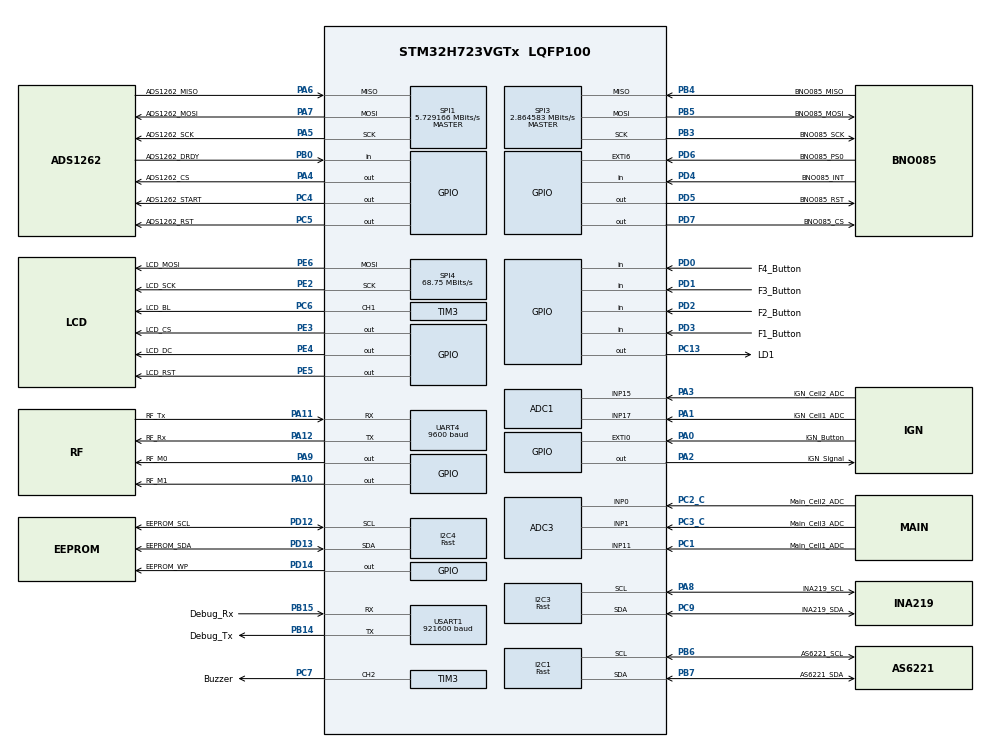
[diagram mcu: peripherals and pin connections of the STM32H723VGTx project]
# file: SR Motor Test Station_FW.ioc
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ADC1.Channel-0\#ChannelRegularConversion=ADC_CHANNEL_17
ADC1.Channel-1\#ChannelRegularConversion=ADC_CHANNEL_15
ADC1.ClockPrescaler=ADC_CLOCK_ASYNC_DIV4
ADC1.ClockPrescalerADC3=ADC_CLOCK_ASYNC_DIV4
ADC1.ContinuousConvMode=ENABLE
ADC1.ConversionDataManagement=ADC_CONVERSIONDATA_DMA_CIRCULAR
ADC1.NbrOfConversion=2
ADC1.NbrOfConversionFlag=1
ADC1.OffsetNumber-0\#ChannelRegularConversion=ADC_OFFSET_NONE
ADC1.OffsetNumber-1\#ChannelRegularConversion=ADC_OFFSET_NONE
ADC1.OffsetSignedSaturation-0\#ChannelRegularConversion=DISABLE
ADC1.OffsetSignedSaturation-1\#ChannelRegularConversion=DISABLE
ADC1.Rank-0\#ChannelRegularConversion=1
ADC1.Rank-1\#ChannelRegularConversion=2
ADC1.SamplingTime-0\#ChannelRegularConversion=ADC_SAMPLETIME_387CYCLES_5
ADC1.SamplingTime-1\#ChannelRegularConversion=ADC_SAMPLETIME_387CYCLES_5
ADC1.master=1
ADC3.Channel-0\#ChannelRegularConversion=ADC_CHANNEL_11
ADC3.Channel-1\#ChannelRegularConversion=ADC_CHANNEL_0
ADC3.Channel-2\#ChannelRegularConversion=ADC_CHANNEL_1
ADC3.ClockPrescaler=ADC_CLOCK_ASYNC_DIV4
ADC3.ClockPrescalerADC3=ADC_CLOCK_ASYNC_DIV4
ADC3.ContinuousConvMode=ENABLE
ADC3.ConversionDataManagement=ADC_CONVERSIONDATA_DMA_CIRCULAR
ADC3.DMAContinuousRequests=ENABLE
ADC3.DiscontinuousConvMode=DISABLE
ADC3.NbrOfConversion=3
ADC3.NbrOfConversionFlag=1
ADC3.OffsetNumber-0\#ChannelRegularConversion=ADC_OFFSET_NONE
ADC3.OffsetNumber-1\#ChannelRegularConversion=ADC_OFFSET_NONE
ADC3.OffsetNumber-2\#ChannelRegularConversion=ADC_OFFSET_NONE
ADC3.OffsetSign-0\#ChannelRegularConversion=ADC3_OFFSET_SIGN_NEGATIVE
ADC3.OffsetSign-1\#ChannelRegularConversion=ADC3_OFFSET_SIGN_NEGATIVE
ADC3.OffsetSign-2\#ChannelRegularConversion=ADC3_OFFSET_SIGN_NEGATIVE
ADC3.Rank-0\#ChannelRegularConversion=1
ADC3.Rank-1\#ChannelRegularConversion=2
ADC3.Rank-2\#ChannelRegularConversion=3
ADC3.SamplingTime-0\#ChannelRegularConversion=ADC3_SAMPLETIME_247CYCLES_5
ADC3.SamplingTime-1\#ChannelRegularConversion=ADC3_SAMPLETIME_247CYCLES_5
ADC3.SamplingTime-2\#ChannelRegularConversion=ADC3_SAMPLETIME_247CYCLES_5
CORTEX_M7.CPU_DCache=Enabled
CORTEX_M7.CPU_ICache=Enabled
CORTEX_M7.default_mode_Activation=1
Dma.ADC1.0.Direction=DMA_PERIPH_TO_MEMORY
Dma.ADC1.0.EventEnable=DISABLE
Dma.ADC1.0.FIFOMode=DMA_FIFOMODE_DISABLE
Dma.ADC1.0.Instance=DMA1_Stream0
Dma.ADC1.0.MemDataAlignment=DMA_MDATAALIGN_HALFWORD
Dma.ADC1.0.MemInc=DMA_MINC_ENABLE
Dma.ADC1.0.Mode=DMA_CIRCULAR
Dma.ADC1.0.PeriphDataAlignment=DMA_PDATAALIGN_HALFWORD
Dma.ADC1.0.PeriphInc=DMA_PINC_DISABLE
Dma.ADC1.0.Polarity=HAL_DMAMUX_REQ_GEN_RISING
Dma.ADC1.0.Priority=DMA_PRIORITY_LOW
Dma.ADC1.0.RequestNumber=1
Dma.ADC1.0.SignalID=NONE
Dma.ADC1.0.SyncEnable=DISABLE
Dma.ADC1.0.SyncPolarity=HAL_DMAMUX_SYNC_NO_EVENT
Dma.ADC1.0.SyncRequestNumber=1
Dma.ADC1.0.SyncSignalID=NONE
Dma.ADC3.1.Direction=DMA_PERIPH_TO_MEMORY
Dma.ADC3.1.EventEnable=DISABLE
Dma.ADC3.1.FIFOMode=DMA_FIFOMODE_DISABLE
Dma.ADC3.1.Instance=DMA1_Stream1
Dma.ADC3.1.MemDataAlignment=DMA_MDATAALIGN_HALFWORD
Dma.ADC3.1.MemInc=DMA_MINC_ENABLE
Dma.ADC3.1.Mode=DMA_CIRCULAR
Dma.ADC3.1.PeriphDataAlignment=DMA_PDATAALIGN_HALFWORD
Dma.ADC3.1.PeriphInc=DMA_PINC_DISABLE
Dma.ADC3.1.Polarity=HAL_DMAMUX_REQ_GEN_RISING
Dma.ADC3.1.Priority=DMA_PRIORITY_LOW
Dma.ADC3.1.RequestNumber=1
Dma.ADC3.1.SignalID=NONE
Dma.ADC3.1.SyncEnable=DISABLE
Dma.ADC3.1.SyncPolarity=HAL_DMAMUX_SYNC_NO_EVENT
Dma.ADC3.1.SyncRequestNumber=1
Dma.ADC3.1.SyncSignalID=NONE
Dma.Request0=ADC1
Dma.Request1=ADC3
Dma.Request2=USART1_TX
Dma.Request3=SPI4_TX
Dma.SPI4_TX.3.Direction=DMA_MEMORY_TO_PERIPH
Dma.SPI4_TX.3.EventEnable=DISABLE
Dma.SPI4_TX.3.FIFOMode=DMA_FIFOMODE_DISABLE
Dma.SPI4_TX.3.Instance=DMA1_Stream3
Dma.SPI4_TX.3.MemDataAlignment=DMA_MDATAALIGN_BYTE
Dma.SPI4_TX.3.MemInc=DMA_MINC_ENABLE
Dma.SPI4_TX.3.Mode=DMA_NORMAL
Dma.SPI4_TX.3.PeriphDataAlignment=DMA_PDATAALIGN_BYTE
Dma.SPI4_TX.3.PeriphInc=DMA_PINC_DISABLE
Dma.SPI4_TX.3.Polarity=HAL_DMAMUX_REQ_GEN_RISING
Dma.SPI4_TX.3.Priority=DMA_PRIORITY_HIGH
Dma.SPI4_TX.3.RequestNumber=1
Dma.SPI4_TX.3.SignalID=NONE
Dma.SPI4_TX.3.SyncEnable=DISABLE
Dma.SPI4_TX.3.SyncPolarity=HAL_DMAMUX_SYNC_NO_EVENT
Dma.SPI4_TX.3.SyncRequestNumber=1
Dma.SPI4_TX.3.SyncSignalID=NONE
Dma.USART1_TX.2.Direction=DMA_MEMORY_TO_PERIPH
Dma.USART1_TX.2.EventEnable=DISABLE
Dma.USART1_TX.2.FIFOMode=DMA_FIFOMODE_DISABLE
Dma.USART1_TX.2.Instance=DMA1_Stream2
Dma.USART1_TX.2.MemDataAlignment=DMA_MDATAALIGN_BYTE
Dma.USART1_TX.2.MemInc=DMA_MINC_ENABLE
Dma.USART1_TX.2.Mode=DMA_NORMAL
Dma.USART1_TX.2.PeriphDataAlignment=DMA_PDATAALIGN_BYTE
Dma.USART1_TX.2.PeriphInc=DMA_PINC_DISABLE
Dma.USART1_TX.2.Polarity=HAL_DMAMUX_REQ_GEN_RISING
Dma.USART1_TX.2.Priority=DMA_PRIORITY_LOW
Dma.USART1_TX.2.RequestNumber=1
Dma.USART1_TX.2.SignalID=NONE
Dma.USART1_TX.2.SyncEnable=DISABLE
Dma.USART1_TX.2.SyncPolarity=HAL_DMAMUX_SYNC_NO_EVENT
Dma.USART1_TX.2.SyncRequestNumber=1
Dma.USART1_TX.2.SyncSignalID=NONE
I2C1.I2C_Speed_Mode=I2C_Fast
I2C1.Timing=0x00D049FB
I2C3.I2C_Speed_Mode=I2C_Fast
I2C3.Timing=0x00D049FB
I2C4.I2C_Speed_Mode=I2C_Fast
I2C4.Timing=0x00D049FB
Mcu.Family=STM32H7
Mcu.Name=STM32H723VGTx
Mcu.Package=LQFP100
NVIC.DMA1_Stream0_IRQn=true\:0\:0\:false\:false\:true\:false\:true\:true
NVIC.DMA1_Stream1_IRQn=true\:0\:0\:false\:false\:true\:false\:true\:true
NVIC.DMA1_Stream2_IRQn=true\:0\:0\:false\:false\:true\:false\:true\:true
NVIC.DMA1_Stream3_IRQn=true\:0\:0\:false\:false\:true\:false\:true\:true
NVIC.PriorityGroup=NVIC_PRIORITYGROUP_4
NVIC.SPI4_IRQn=true\:0\:0\:false\:false\:true\:false\:true\:true
NVIC.USART1_IRQn=true\:0\:0\:false\:true\:true\:1\:true\:true\:true
PA0.GPIO_Label=IGN_Button
PA0.Signal=GPXTI0
PA1.GPIO_Label=IGN_Cell1_ADC
PA1.Mode=IN17-Single-Ended
PA1.Signal=ADC1_INP17
PA10.GPIO_Label=RF_M1
PA10.Signal=GPIO_Output
PA11.GPIO_Label=RF_Tx
PA11.Mode=Asynchronous
PA11.Signal=UART4_RX
PA12.GPIO_Label=RF_Rx
PA12.Mode=Asynchronous
PA12.Signal=UART4_TX
PA13(JTMS/SWDIO).Mode=Serial_Wire
PA13(JTMS/SWDIO).Signal=DEBUG_JTMS-SWDIO
PA14(JTCK/SWCLK).Mode=Serial_Wire
PA14(JTCK/SWCLK).Signal=DEBUG_JTCK-SWCLK
PA2.GPIO_Label=IGN_Signal
PA2.Signal=GPIO_Output
PA3.GPIO_Label=IGN_Cell2_ADC
PA3.Signal=ADCx_INP15
PA4.GPIO_Label=ADS1262_CS
PA4.Signal=GPIO_Output
PA5.GPIO_Label=ADS1262_SCK
PA5.Mode=Full_Duplex_Master
PA5.Signal=SPI1_SCK
PA6.GPIO_Label=ADS1262_MISO
PA6.Mode=Full_Duplex_Master
PA6.Signal=SPI1_MISO
PA7.GPIO_Label=ADS1262_MOSI
PA7.Mode=Full_Duplex_Master
PA7.Signal=SPI1_MOSI
PA8.GPIO_Label=INA219_SCL
PA8.Mode=I2C
PA8.Signal=I2C3_SCL
PA9.GPIO_Label=RF_M0
PA9.Signal=GPIO_Output
PB0.GPIO_Label=ADS1262_DRDY
PB0.Signal=GPIO_Input
PB14.GPIO_Label=Debug_Tx
PB14.Mode=Asynchronous
PB14.Signal=USART1_TX
PB15.GPIO_Label=Debug_Rx
PB15.Mode=Asynchronous
PB15.Signal=USART1_RX
PB3(JTDO/TRACESWO).GPIO_Label=BNO085_SCK
PB3(JTDO/TRACESWO).Mode=Full_Duplex_Master
PB3(JTDO/TRACESWO).Signal=SPI3_SCK
PB4(NJTRST).GPIO_Label=BNO085_MISO
PB4(NJTRST).Mode=Full_Duplex_Master
PB4(NJTRST).Signal=SPI3_MISO
PB5.GPIO_Label=BNO085_MOSI
PB5.Mode=Full_Duplex_Master
PB5.Signal=SPI3_MOSI
PB6.GPIO_Label=AS6221_SCL
PB6.Mode=I2C
PB6.Signal=I2C1_SCL
PB7.GPIO_Label=AS6221_SDA
PB7.Mode=I2C
PB7.Signal=I2C1_SDA
PC1.GPIO_Label=Main_Cell1_ADC
PC1.Signal=ADCx_INP11
PC13.GPIO_Label=LD1
PC13.Signal=GPIO_Output
PC2_C.GPIO_Label=Main_Cell2_ADC
PC2_C.Mode=IN0-Single-Ended
PC2_C.Signal=ADC3_INP0
PC3_C.GPIO_Label=Main_Cell3_ADC
PC3_C.Mode=IN1-Single-Ended
PC3_C.Signal=ADC3_INP1
PC4.GPIO_Label=ADS1262_START
PC4.Signal=GPIO_Output
PC5.GPIO_Label=ADS1262_RST
PC5.Signal=GPIO_Output
PC6.GPIO_Label=LCD_BL
PC6.GPIO_Speed=GPIO_SPEED_FREQ_VERY_HIGH
PC6.Signal=S_TIM3_CH1
PC7.GPIO_Label=Buzzer
PC7.Signal=S_TIM3_CH2
PC9.GPIO_Label=INA219_SDA
PC9.Mode=I2C
PC9.Signal=I2C3_SDA
PD0.GPIO_Label=F4_Button
PD0.Signal=GPIO_Input
PD1.GPIO_Label=F3_Button
PD1.Signal=GPIO_Input
PD12.GPIO_Label=EEPROM_SCL
PD12.Mode=I2C
PD12.Signal=I2C4_SCL
PD13.GPIO_Label=EEPROM_SDA
PD13.Mode=I2C
PD13.Signal=I2C4_SDA
PD14.GPIO_Label=EEPROM_WP
PD14.Signal=GPIO_Output
PD2.GPIO_Label=F2_Button
PD2.Signal=GPIO_Input
PD3.GPIO_Label=F1_Button
PD3.Signal=GPIO_Input
PD4.GPIO_Label=BNO085_INT
PD4.Signal=GPIO_Input
PD5.GPIO_Label=BNO085_RST
PD5.Signal=GPIO_Output
PD6.GPIO_Label=BNO085_PS0
PD6.Signal=GPXTI6
PD7.GPIO_Label=BNO085_CS
PD7.Signal=GPIO_Output
PE2.GPIO_Label=LCD_SCK
PE2.GPIO_PuPd=GPIO_PULLDOWN
PE2.GPIO_Speed=GPIO_SPEED_FREQ_VERY_HIGH
PE2.Mode=TX_Only_Simplex_Unidirect_Master
PE2.Signal=SPI4_SCK
PE3.GPIO_Label=LCD_CS
PE3.GPIO_Speed=GPIO_SPEED_FREQ_VERY_HIGH
PE3.PinState=GPIO_PIN_SET
PE3.Signal=GPIO_Output
PE4.GPIO_Label=LCD_DC
PE4.GPIO_Speed=GPIO_SPEED_FREQ_VERY_HIGH
PE4.PinState=GPIO_PIN_SET
PE4.Signal=GPIO_Output
PE5.GPIO_Label=LCD_RST
PE5.GPIO_Speed=GPIO_SPEED_FREQ_VERY_HIGH
PE5.PinState=GPIO_PIN_SET
PE5.Signal=GPIO_Output
PE6.GPIO_Label=LCD_MOSI
PE6.GPIO_Speed=GPIO_SPEED_FREQ_VERY_HIGH
PE6.Mode=TX_Only_Simplex_Unidirect_Master
PE6.Signal=SPI4_MOSI
PH0-OSC_IN.Mode=HSE-External-Oscillator
PH0-OSC_IN.Signal=RCC_OSC_IN
PH1-OSC_OUT.Mode=HSE-External-Oscillator
PH1-OSC_OUT.Signal=RCC_OSC_OUT
ProjectManager.HeapSize=0x200
ProjectManager.StackSize=0x400
ProjectManager.TargetToolchain=STM32CubeIDE
RCC.ADCFreq_Value=96000000
RCC.APB1Freq_Value=137500000
RCC.APB2Freq_Value=137500000
RCC.APB3Freq_Value=137500000
RCC.APB4Freq_Value=137500000
RCC.CortexFreq_Value=550000000
RCC.D1PPRE=RCC_APB3_DIV2
RCC.D2PPRE1=RCC_APB1_DIV2
RCC.D2PPRE2=RCC_APB2_DIV2
RCC.D3PPRE=RCC_APB4_DIV2
RCC.DIVM1=3
RCC.DIVM2=1
RCC.DIVN1=137
RCC.DIVN2=16
RCC.DIVP1=1
RCC.DIVQ1=3
RCC.HCLKFreq_Value=275000000
RCC.HPRE=RCC_HCLK_DIV2
RCC.HSE_VALUE=12000000
RCC.PLL2FRACN=0
RCC.PLLFRACN=4096
RCC.PLLSourceVirtual=RCC_PLLSOURCE_HSE
RCC.SYSCLKFreq_VALUE=550000000
RCC.SYSCLKSource=RCC_SYSCLKSOURCE_PLLCLK
RCC.USBFreq_Value=183333333.33333334
SH.ADCx_INP11.0=ADC3_INP11,IN11-Single-Ended
SH.ADCx_INP15.0=ADC1_INP15,IN15-Single-Ended
SH.S_TIM3_CH1.0=TIM3_CH1,PWM Generation1 CH1
SH.S_TIM3_CH2.0=TIM3_CH2,PWM Generation2 CH2
SPI1.BaudRatePrescaler=SPI_BAUDRATEPRESCALER_32
SPI1.CLKPhase=SPI_PHASE_2EDGE
SPI1.CalculateBaudRate=5.729166 MBits/s
SPI1.DataSize=SPI_DATASIZE_8BIT
SPI1.Direction=SPI_DIRECTION_2LINES
SPI1.Mode=SPI_MODE_MASTER
SPI1.VirtualType=VM_MASTER
SPI3.BaudRatePrescaler=SPI_BAUDRATEPRESCALER_64
SPI3.CLKPhase=SPI_PHASE_2EDGE
SPI3.CLKPolarity=SPI_POLARITY_HIGH
SPI3.CalculateBaudRate=2.864583 MBits/s
SPI3.DataSize=SPI_DATASIZE_8BIT
SPI3.Direction=SPI_DIRECTION_2LINES
SPI3.Mode=SPI_MODE_MASTER
SPI3.VirtualType=VM_MASTER
SPI4.BaudRatePrescaler=SPI_BAUDRATEPRESCALER_2
SPI4.CalculateBaudRate=68.75 MBits/s
SPI4.DataSize=SPI_DATASIZE_8BIT
SPI4.Direction=SPI_DIRECTION_2LINES_TXONLY
SPI4.Mode=SPI_MODE_MASTER
SPI4.VirtualType=VM_MASTER
TIM3.AutoReloadPreload=TIM_AUTORELOAD_PRELOAD_ENABLE
TIM3.Channel-PWM\ Generation1\ CH1=TIM_CHANNEL_1
TIM3.Channel-PWM\ Generation2\ CH2=TIM_CHANNEL_2
TIM3.Period=999
TIM3.Prescaler=13
UART4.BaudRate=9600
USART1.BaudRate=921600
USART1.VirtualMode-Asynchronous=VM_ASYNC
VP_MEMORYMAP_VS_MEMORYMAP.Mode=CurAppReg
VP_TIM3_VS_ClockSourceINT.Mode=Internal
board=custom

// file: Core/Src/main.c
/* USER CODE BEGIN Header */
/**
  ******************************************************************************
  * @file           : main.c
  * @brief          : Main program body
  ******************************************************************************
  * @attention
  *
  * Copyright (c) 2025 STMicroelectronics.
  * All rights reserved.
  *
  * This software is licensed under terms that can be found in the LICENSE file
  * in the root directory of this software component.
  * If no LICENSE file comes with this software, it is provided AS-IS.
  *
  ******************************************************************************
  */
/* USER CODE END Header */
#include "main.h"
#include "adc.h"
#include "dma.h"
#include "i2c.h"
#include "spi.h"
#include "tim.h"
#include "usart.h"
#include "gpio.h"

/* USER CODE BEGIN Includes */
#include "stdio.h"
#include "../../lvgl/lvgl.h"
#include "../../lvgl/demos/benchmark/lv_demo_benchmark.h"
#include "LCD_2inch_st7789_v9_dma.h"
#include "DEV_Config_h7.h"
#include "LVGL9_ST7789_Port_ULP.h"

/* USER CODE END Includes */

/* USER CODE BEGIN PM */
int _write(int file, char* p, int len){
	HAL_UART_Transmit(&huart1, p, len, 10);
	return len;
}

/* USER CODE END PM */

void SystemClock_Config(void);
void PeriphCommonClock_Config(void);
static void MPU_Config(void);
static void MX_NVIC_Init(void);

int main(void)
{

  /* MPU Configuration--------------------------------------------------------*/
  MPU_Config();

  /* Enable the CPU Cache */

  /* Enable I-Cache---------------------------------------------------------*/
  SCB_EnableICache();

  /* Enable D-Cache---------------------------------------------------------*/
  SCB_EnableDCache();

  /* MCU Configuration--------------------------------------------------------*/

  /* Reset of all peripherals, Initializes the Flash interface and the Systick. */
  HAL_Init();

  /* Configure the system clock */
  SystemClock_Config();

  /* Configure the peripherals common clocks */
  PeriphCommonClock_Config();

  /* Initialize all configured peripherals */
  MX_GPIO_Init();
  MX_DMA_Init();
  MX_ADC1_Init();
  MX_ADC3_Init();
  MX_I2C1_Init();
  MX_I2C3_Init();
  MX_I2C4_Init();
  MX_SPI1_Init();
  MX_SPI3_Init();
  MX_SPI4_Init();
  MX_TIM3_Init();
  MX_USART1_UART_Init();
  MX_UART4_Init();

  /* Initialize interrupts */
  MX_NVIC_Init();
  /* USER CODE BEGIN 2 */
  lv_init();
  lv_port_disp_init_st7789_v9_ulp();

  /* USER CODE END 2 */

  /* Infinite loop */
  /* USER CODE BEGIN WHILE */
  while (1)
  {
	  lv_timer_handler(); // LVGL 내부 이벤트 처리
	  HAL_Delay(5);       // 주기적 호출
    /* USER CODE END WHILE */

  }
}

void SystemClock_Config(void)
{
  RCC_OscInitTypeDef RCC_OscInitStruct = {0};
  RCC_ClkInitTypeDef RCC_ClkInitStruct = {0};

  /** Supply configuration update enable
  */
  HAL_PWREx_ConfigSupply(PWR_LDO_SUPPLY);

  /** Configure the main internal regulator output voltage
  */
  __HAL_PWR_VOLTAGESCALING_CONFIG(PWR_REGULATOR_VOLTAGE_SCALE0);

  while(!__HAL_PWR_GET_FLAG(PWR_FLAG_VOSRDY)) {}

  /** Initializes the RCC Oscillators according to the specified parameters
  * in the RCC_OscInitTypeDef structure.
  */
  RCC_OscInitStruct.OscillatorType = RCC_OSCILLATORTYPE_HSE;
  RCC_OscInitStruct.HSEState = RCC_HSE_ON;
  RCC_OscInitStruct.PLL.PLLState = RCC_PLL_ON;
  RCC_OscInitStruct.PLL.PLLSource = RCC_PLLSOURCE_HSE;
  RCC_OscInitStruct.PLL.PLLM = 3;
  RCC_OscInitStruct.PLL.PLLN = 137;
  RCC_OscInitStruct.PLL.PLLP = 1;
  RCC_OscInitStruct.PLL.PLLQ = 3;
  RCC_OscInitStruct.PLL.PLLR = 2;
  RCC_OscInitStruct.PLL.PLLRGE = RCC_PLL1VCIRANGE_2;
  RCC_OscInitStruct.PLL.PLLVCOSEL = RCC_PLL1VCOWIDE;
  RCC_OscInitStruct.PLL.PLLFRACN = 4096;
  if (HAL_RCC_OscConfig(&RCC_OscInitStruct) != HAL_OK)
  {
    Error_Handler();
  }

  /** Initializes the CPU, AHB and APB buses clocks
  */
  RCC_ClkInitStruct.ClockType = RCC_CLOCKTYPE_HCLK|RCC_CLOCKTYPE_SYSCLK
                              |RCC_CLOCKTYPE_PCLK1|RCC_CLOCKTYPE_PCLK2
                              |RCC_CLOCKTYPE_D3PCLK1|RCC_CLOCKTYPE_D1PCLK1;
  RCC_ClkInitStruct.SYSCLKSource = RCC_SYSCLKSOURCE_PLLCLK;
  RCC_ClkInitStruct.SYSCLKDivider = RCC_SYSCLK_DIV1;
  RCC_ClkInitStruct.AHBCLKDivider = RCC_HCLK_DIV2;
  RCC_ClkInitStruct.APB3CLKDivider = RCC_APB3_DIV2;
  RCC_ClkInitStruct.APB1CLKDivider = RCC_APB1_DIV2;
  RCC_ClkInitStruct.APB2CLKDivider = RCC_APB2_DIV2;
  RCC_ClkInitStruct.APB4CLKDivider = RCC_APB4_DIV2;

  if (HAL_RCC_ClockConfig(&RCC_ClkInitStruct, FLASH_LATENCY_3) != HAL_OK)
  {
    Error_Handler();
  }
}

void PeriphCommonClock_Config(void)
{
  RCC_PeriphCLKInitTypeDef PeriphClkInitStruct = {0};

  /** Initializes the peripherals clock
  */
  PeriphClkInitStruct.PeriphClockSelection = RCC_PERIPHCLK_ADC;
  PeriphClkInitStruct.PLL2.PLL2M = 1;
  PeriphClkInitStruct.PLL2.PLL2N = 16;
  PeriphClkInitStruct.PLL2.PLL2P = 2;
  PeriphClkInitStruct.PLL2.PLL2Q = 2;
  PeriphClkInitStruct.PLL2.PLL2R = 2;
  PeriphClkInitStruct.PLL2.PLL2RGE = RCC_PLL2VCIRANGE_3;
  PeriphClkInitStruct.PLL2.PLL2VCOSEL = RCC_PLL2VCOWIDE;
  PeriphClkInitStruct.PLL2.PLL2FRACN = 0;
  PeriphClkInitStruct.AdcClockSelection = RCC_ADCCLKSOURCE_PLL2;
  if (HAL_RCCEx_PeriphCLKConfig(&PeriphClkInitStruct) != HAL_OK)
  {
    Error_Handler();
  }
}

/**
  * @brief NVIC Configuration.
  * @retval None
  */
static void MX_NVIC_Init(void)
{
  /* USART1_IRQn interrupt configuration */
  HAL_NVIC_SetPriority(USART1_IRQn, 0, 0);
  HAL_NVIC_EnableIRQ(USART1_IRQn);
}

 /* MPU Configuration */

void MPU_Config(void)
{
  MPU_Region_InitTypeDef MPU_InitStruct = {0};

  /* Disables the MPU */
  HAL_MPU_Disable();

  /** Initializes and configures the Region and the memory to be protected
  */
  MPU_InitStruct.Enable = MPU_REGION_ENABLE;
  MPU_InitStruct.Number = MPU_REGION_NUMBER0;
  MPU_InitStruct.BaseAddress = 0x0;
  MPU_InitStruct.Size = MPU_REGION_SIZE_4GB;
  MPU_InitStruct.SubRegionDisable = 0x87;
  MPU_InitStruct.TypeExtField = MPU_TEX_LEVEL0;
  MPU_InitStruct.AccessPermission = MPU_REGION_NO_ACCESS;
  MPU_InitStruct.DisableExec = MPU_INSTRUCTION_ACCESS_DISABLE;
  MPU_InitStruct.IsShareable = MPU_ACCESS_SHAREABLE;
  MPU_InitStruct.IsCacheable = MPU_ACCESS_NOT_CACHEABLE;
  MPU_InitStruct.IsBufferable = MPU_ACCESS_NOT_BUFFERABLE;

  HAL_MPU_ConfigRegion(&MPU_InitStruct);
  /* Enables the MPU */
  HAL_MPU_Enable(MPU_PRIVILEGED_DEFAULT);

}

void Error_Handler(void)
{
  __disable_irq();
  while (1)
  {
  }
}
